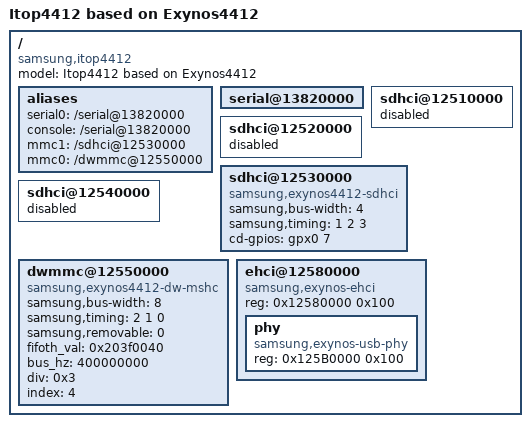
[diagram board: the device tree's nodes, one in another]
// SPDX-License-Identifier: GPL-2.0+
/*
 * Odroid-U3/X2 board device tree source
 *
 * Copyright (c) 2014 Samsung Electronics Co., Ltd.
 *		http://www.samsung.com
 */

/dts-v1/;
#include "exynos4412.dtsi"

/ {
	model = "Itop4412 based on Exynos4412";
	compatible = "samsung,itop4412", "samsung,exynos4412";

	aliases {
		serial0 = "/serial@13820000";
		console = "/serial@13820000";
		mmc1 = "/sdhci@12530000";
		mmc0 = "/dwmmc@12550000";
	};
	
	serial@13820000 {
		status = "okay";
	};
	
	sdhci@12510000 {
		status = "disabled";
	};

	sdhci@12520000 {
		status = "disabled";
	};

	sdhci@12530000 {
		compatible = "samsung,exynos4412-sdhci";
		samsung,bus-width = <4>;
		samsung,timing = <1 2 3>;
		cd-gpios = <&gpx0 7 0>;
		status = "okay";
	};

	sdhci@12540000 {
		status = "disabled";
	};

	dwmmc@12550000 {
		compatible = "samsung,exynos4412-dw-mshc";
		samsung,bus-width = <8>;
		samsung,timing = <2 1 0>;
		samsung,removable = <0>;
		fifoth_val = <0x203f0040>;
		bus_hz = <400000000>;
		div = <0x3>;
		index = <4>;
		status = "okay";
	};
	
	ehci@12580000 {
		compatible = "samsung,exynos-ehci";
		reg = <0x12580000 0x100>;
		#address-cells = <1>;
		#size-cells = <1>;
		phy {
			compatible = "samsung,exynos-usb-phy";
			reg = <0x125B0000 0x100>;
		};
	};
};
